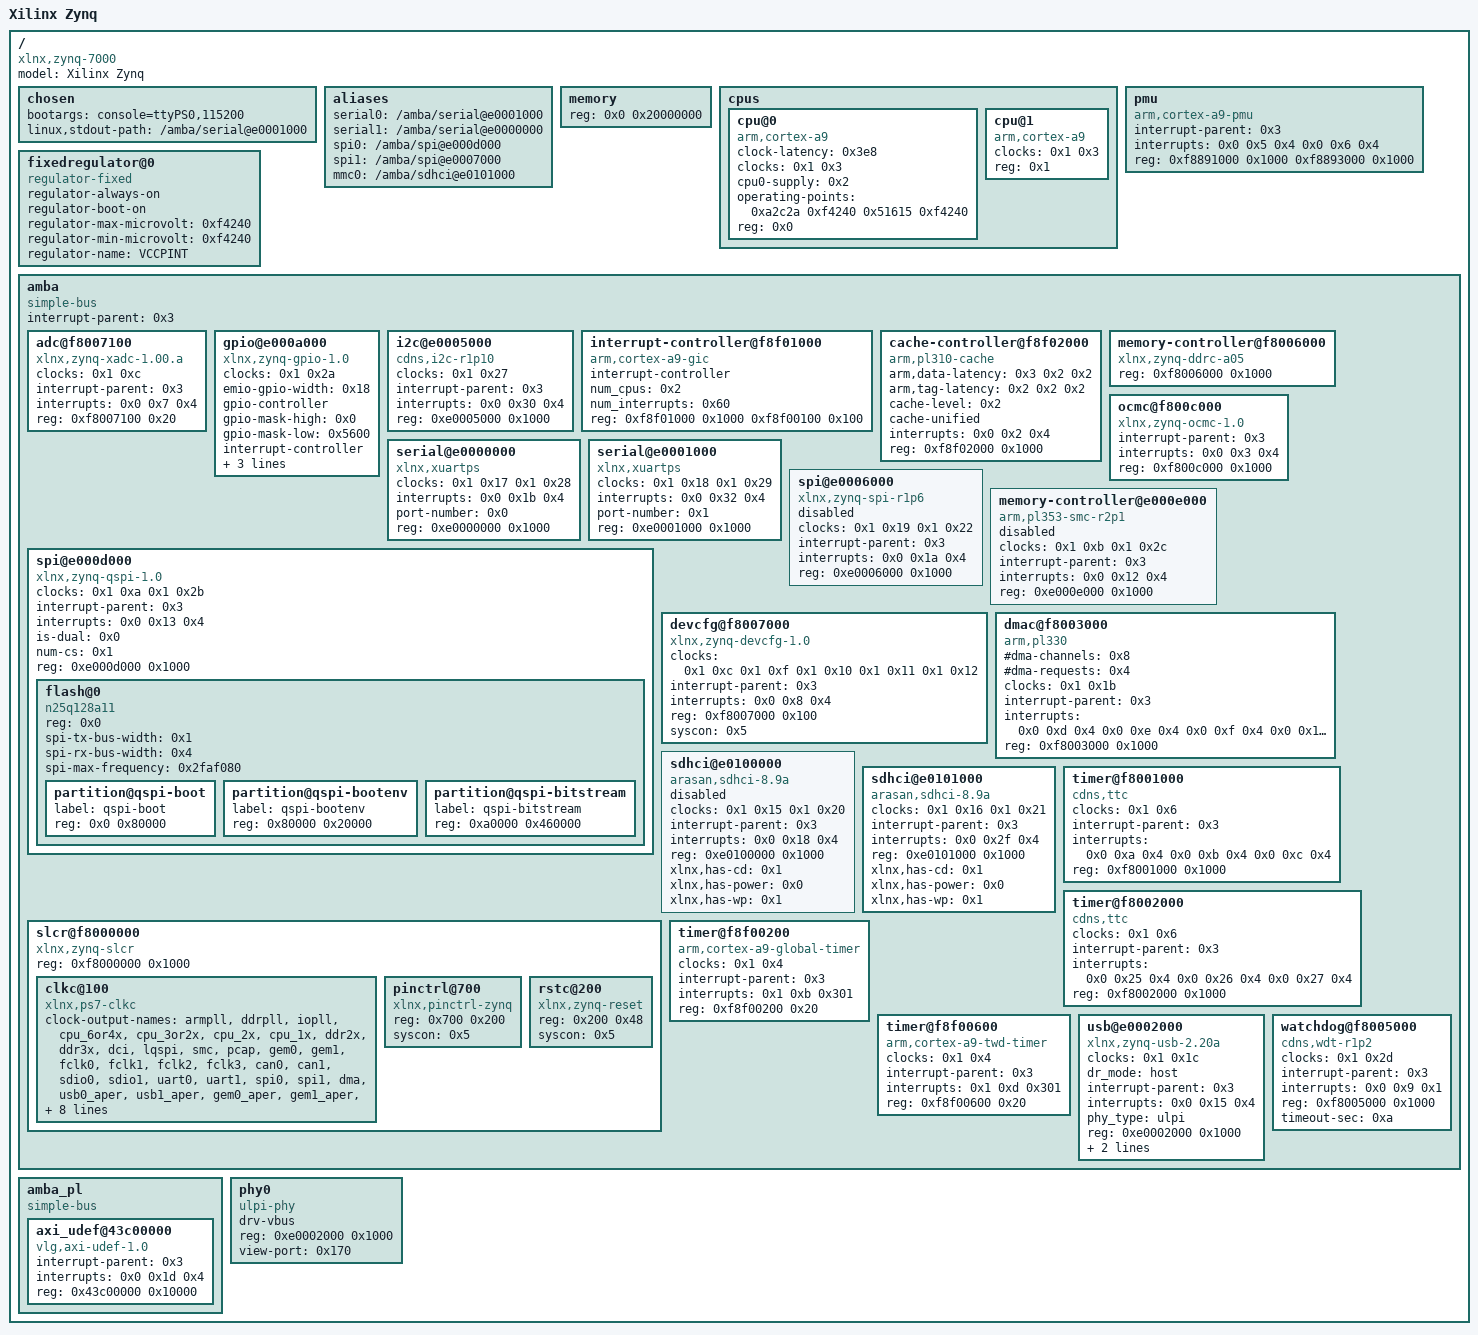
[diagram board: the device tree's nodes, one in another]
/dts-v1/;

/ {
	#address-cells = <0x1>;
	#size-cells = <0x1>;
	compatible = "xlnx,zynq-7000";
	model = "Xilinx Zynq";

	chosen {
		bootargs = "console=ttyPS0,115200";
		linux,stdout-path = "/amba/serial@e0001000";
	};

	aliases {
		serial0 = "/amba/serial@e0001000";
		serial1 = "/amba/serial@e0000000";
		spi0 = "/amba/spi@e000d000";
		spi1 = "/amba/spi@e0007000";
		mmc0 = "/amba/sdhci@e0101000";
	};


	memory {
		device_type = "memory";
		reg = <0x0 0x20000000>;
	};

	cpus {
		#address-cells = <0x1>;
		#size-cells = <0x0>;

		cpu@0 {
			clock-latency = <0x3e8>;
			clocks = <0x1 0x3>;
			compatible = "arm,cortex-a9";
			cpu0-supply = <0x2>;
			device_type = "cpu";
			operating-points = <0xa2c2a 0xf4240 0x51615 0xf4240>;
			reg = <0x0>;
		};

		cpu@1 {
			clocks = <0x1 0x3>;
			compatible = "arm,cortex-a9";
			device_type = "cpu";
			reg = <0x1>;
		};
	};

	pmu {
		compatible = "arm,cortex-a9-pmu";
		interrupt-parent = <0x3>;
		interrupts = <0x0 0x5 0x4 0x0 0x6 0x4>;
		reg = <0xf8891000 0x1000 0xf8893000 0x1000>;
	};

	fixedregulator@0 {
		compatible = "regulator-fixed";
		linux,phandle = <0x2>;
		phandle = <0x2>;
		regulator-always-on;
		regulator-boot-on;
		regulator-max-microvolt = <0xf4240>;
		regulator-min-microvolt = <0xf4240>;
		regulator-name = "VCCPINT";
	};




	amba {
		#address-cells = <0x1>;
		#size-cells = <0x1>;
		compatible = "simple-bus";
		interrupt-parent = <0x3>;
		linux,phandle = <0xa>;
		phandle = <0xa>;
		ranges;

		adc@f8007100 {
			clocks = <0x1 0xc>;
			compatible = "xlnx,zynq-xadc-1.00.a";
			interrupt-parent = <0x3>;
			interrupts = <0x0 0x7 0x4>;
			linux,phandle = <0xb>;
			phandle = <0xb>;
			reg = <0xf8007100 0x20>;
		};
		gpio@e000a000 {
			#gpio-cells = <0x2>;
			#interrupt-cells = <0x2>;
			clocks = <0x1 0x2a>;
			compatible = "xlnx,zynq-gpio-1.0";
			emio-gpio-width = <0x18>;
			gpio-controller;
			gpio-mask-high = <0x0>;
			gpio-mask-low = <0x5600>;
			interrupt-controller;
			interrupt-parent = <0x3>;
			interrupts = <0x0 0x14 0x4>;
			linux,phandle = <0x6>;
			phandle = <0x6>;
			reg = <0xe000a000 0x1000>;
		};
		i2c@e0005000 {
			#address-cells = <0x1>;
			#size-cells = <0x0>;
			clocks = <0x1 0x27>;
			compatible = "cdns,i2c-r1p10";
			interrupt-parent = <0x3>;
			interrupts = <0x0 0x30 0x4>;
			linux,phandle = <0xf>;
			phandle = <0xf>;
			reg = <0xe0005000 0x1000>;
			status = "okay";
		};

		interrupt-controller@f8f01000 {
			#interrupt-cells = <0x3>;
			compatible = "arm,cortex-a9-gic";
			interrupt-controller;
			linux,phandle = <0x3>;
			num_cpus = <0x2>;
			num_interrupts = <0x60>;
			phandle = <0x3>;
			reg = <0xf8f01000 0x1000 0xf8f00100 0x100>;
		};

		cache-controller@f8f02000 {
			arm,data-latency = <0x3 0x2 0x2>;
			arm,tag-latency = <0x2 0x2 0x2>;
			cache-level = <0x2>;
			cache-unified;
			compatible = "arm,pl310-cache";
			interrupts = <0x0 0x2 0x4>;
			linux,phandle = <0x10>;
			phandle = <0x10>;
			reg = <0xf8f02000 0x1000>;
		};
		memory-controller@f8006000 {
			compatible = "xlnx,zynq-ddrc-a05";
			linux,phandle = <0x11>;
			phandle = <0x11>;
			reg = <0xf8006000 0x1000>;
		};

		ocmc@f800c000 {
			compatible = "xlnx,zynq-ocmc-1.0";
			interrupt-parent = <0x3>;
			interrupts = <0x0 0x3 0x4>;
			linux,phandle = <0x12>;
			phandle = <0x12>;
			reg = <0xf800c000 0x1000>;
		};
		serial@e0000000 {
			clock-names = "uart_clk", "pclk";
			clocks = <0x1 0x17 0x1 0x28>;
			compatible = "xlnx,xuartps", "cdns,uart-r1p8";
			device_type = "serial";
			interrupts = <0x0 0x1b 0x4>;
			linux,phandle = <0x13>;
			phandle = <0x13>;
			port-number = <0x0>;
			reg = <0xe0000000 0x1000>;
			status = "okay";
		};

		serial@e0001000 {
			clock-names = "uart_clk", "pclk";
			clocks = <0x1 0x18 0x1 0x29>;
			compatible = "xlnx,xuartps", "cdns,uart-r1p8";
			device_type = "serial";
			interrupts = <0x0 0x32 0x4>;
			linux,phandle = <0x14>;
			phandle = <0x14>;
			port-number = <0x1>;
			reg = <0xe0001000 0x1000>;
			status = "okay";
		};
		spi@e0006000 {
			#address-cells = <0x1>;
			#size-cells = <0x0>;
			clock-names = "ref_clk", "pclk";
			clocks = <0x1 0x19 0x1 0x22>;
			compatible = "xlnx,zynq-spi-r1p6";
			interrupt-parent = <0x3>;
			interrupts = <0x0 0x1a 0x4>;
			linux,phandle = <0x15>;
			phandle = <0x15>;
			reg = <0xe0006000 0x1000>;
			status = "disabled";
		};

		spi@e000d000 {
			#address-cells = <0x1>;
			#size-cells = <0x0>;
			clock-names = "ref_clk", "pclk";
			clocks = <0x1 0xa 0x1 0x2b>;
			compatible = "xlnx,zynq-qspi-1.0";
			interrupt-parent = <0x3>;
			interrupts = <0x0 0x13 0x4>;
			is-dual = <0x0>;
			linux,phandle = <0x17>;
			num-cs = <0x1>;
			phandle = <0x17>;
			reg = <0xe000d000 0x1000>;
			status = "okay";

			flash@0 {
				compatible = "n25q128a11";
				reg = <0x0>;
				spi-tx-bus-width = <0x1>;
				spi-rx-bus-width = <0x4>;
				spi-max-frequency = <0x2faf080>;
				#address-cells = <0x1>;
				#size-cells = <0x1>;

				partition@qspi-boot {
					label = "qspi-boot";
					reg = <0x0 0x80000>;
				};

				partition@qspi-bootenv {
					label = "qspi-bootenv";
					reg = <0x80000 0x20000>;
				};

				partition@qspi-bitstream {
					label = "qspi-bitstream";
					reg = <0xa0000 0x460000>;
				};

			};
		};
		memory-controller@e000e000 {
			#address-cells = <0x1>;
			#size-cells = <0x1>;
			clock-names = "memclk", "aclk";
			clocks = <0x1 0xb 0x1 0x2c>;
			compatible = "arm,pl353-smc-r2p1";
			interrupt-parent = <0x3>;
			interrupts = <0x0 0x12 0x4>;
			linux,phandle = <0x18>;
			phandle = <0x18>;
			ranges;
			reg = <0xe000e000 0x1000>;
			status = "disabled";
		};

		devcfg@f8007000 {
			clock-names = "ref_clk", "fclk0", "fclk1", "fclk2", "fclk3";
			clocks = <0x1 0xc 0x1 0xf 0x1 0x10 0x1 0x11 0x1 0x12>;
			compatible = "xlnx,zynq-devcfg-1.0";
			interrupt-parent = <0x3>;
			interrupts = <0x0 0x8 0x4>;
			linux,phandle = <0x22>;
			phandle = <0x22>;
			reg = <0xf8007000 0x100>;
			syscon = <0x5>;
		};

		dmac@f8003000 {
			#dma-cells = <0x1>;
			#dma-channels = <0x8>;
			#dma-requests = <0x4>;
			clock-names = "apb_pclk";
			clocks = <0x1 0x1b>;
			compatible = "arm,pl330", "arm,primecell";
			interrupt-names = "abort", "dma0", "dma1", "dma2", "dma3", "dma4", "dma5", "dma6", "dma7";
			interrupt-parent = <0x3>;
			interrupts = <0x0 0xd 0x4 0x0 0xe 0x4 0x0 0xf 0x4 0x0 0x10 0x4 0x0 0x11 0x4 0x0 0x28 0x4 0x0 0x29 0x4 0x0 0x2a 0x4 0x0 0x2b 0x4>;
			linux,phandle = <0x21>;
			phandle = <0x21>;
			reg = <0xf8003000 0x1000>;
		};





		sdhci@e0100000 {
			clock-names = "clk_xin", "clk_ahb";
			clocks = <0x1 0x15 0x1 0x20>;
			compatible = "arasan,sdhci-8.9a";
			interrupt-parent = <0x3>;
			interrupts = <0x0 0x18 0x4>;
			linux,phandle = <0x1d>;
			phandle = <0x1d>;
			reg = <0xe0100000 0x1000>;
			status = "disabled";
			xlnx,has-cd = <0x1>;
			xlnx,has-power = <0x0>;
			xlnx,has-wp = <0x1>;
		};

		sdhci@e0101000 {
			clock-names = "clk_xin", "clk_ahb";
			clocks = <0x1 0x16 0x1 0x21>;
			compatible = "arasan,sdhci-8.9a";
			interrupt-parent = <0x3>;
			interrupts = <0x0 0x2f 0x4>;
			linux,phandle = <0x1e>;
			phandle = <0x1e>;
			reg = <0xe0101000 0x1000>;
			status = "okay";
			xlnx,has-cd = <0x1>;
			xlnx,has-power = <0x0>;
			xlnx,has-wp = <0x1>;
		};


		slcr@f8000000 {
			#address-cells = <0x1>;
			#size-cells = <0x1>;
			compatible = "xlnx,zynq-slcr", "syscon", "simple-bus";
			linux,phandle = <0x5>;
			phandle = <0x5>;
			ranges;
			reg = <0xf8000000 0x1000>;

			clkc@100 {
				#clock-cells = <0x1>;
				clock-output-names = "armpll", "ddrpll", "iopll", "cpu_6or4x", "cpu_3or2x", "cpu_2x", "cpu_1x", "ddr2x", "ddr3x", "dci", "lqspi", "smc", "pcap", "gem0", "gem1", "fclk0", "fclk1", "fclk2", "fclk3", "can0", "can1", "sdio0", "sdio1", "uart0", "uart1", "spi0", "spi1", "dma", "usb0_aper", "usb1_aper", "gem0_aper", "gem1_aper", "sdio0_aper", "sdio1_aper", "spi0_aper", "spi1_aper", "can0_aper", "can1_aper", "i2c0_aper", "i2c1_aper", "uart0_aper", "uart1_aper", "gpio_aper", "lqspi_aper", "smc_aper", "swdt", "dbg_trc", "dbg_apb";
				compatible = "xlnx,ps7-clkc";
				fclk-enable = <0xf>;
				linux,phandle = <0x1>;
				phandle = <0x1>;
				ps-clk-frequency = <0x1fca055>;
				reg = <0x100 0x100>;
			};

			pinctrl@700 {
				compatible = "xlnx,pinctrl-zynq";
				linux,phandle = <0x20>;
				phandle = <0x20>;
				reg = <0x700 0x200>;
				syscon = <0x5>;
			};

			rstc@200 {
				#reset-cells = <0x1>;
				compatible = "xlnx,zynq-reset";
				linux,phandle = <0x1f>;
				phandle = <0x1f>;
				reg = <0x200 0x48>;
				syscon = <0x5>;
			};
		};


		timer@f8001000 {
			clocks = <0x1 0x6>;
			compatible = "cdns,ttc";
			interrupt-parent = <0x3>;
			interrupts = <0x0 0xa 0x4 0x0 0xb 0x4 0x0 0xc 0x4>;
			linux,phandle = <0x24>;
			phandle = <0x24>;
			reg = <0xf8001000 0x1000>;
		};

		timer@f8002000 {
			clocks = <0x1 0x6>;
			compatible = "cdns,ttc";
			interrupt-parent = <0x3>;
			interrupts = <0x0 0x25 0x4 0x0 0x26 0x4 0x0 0x27 0x4>;
			linux,phandle = <0x25>;
			phandle = <0x25>;
			reg = <0xf8002000 0x1000>;
		};

		timer@f8f00200 {
			clocks = <0x1 0x4>;
			compatible = "arm,cortex-a9-global-timer";
			interrupt-parent = <0x3>;
			interrupts = <0x1 0xb 0x301>;
			linux,phandle = <0x23>;
			phandle = <0x23>;
			reg = <0xf8f00200 0x20>;
		};

		timer@f8f00600 {
			clocks = <0x1 0x4>;
			compatible = "arm,cortex-a9-twd-timer";
			interrupt-parent = <0x3>;
			interrupts = <0x1 0xd 0x301>;
			linux,phandle = <0x26>;
			phandle = <0x26>;
			reg = <0xf8f00600 0x20>;
		};

		usb@e0002000 {
			clocks = <0x1 0x1c>;
			compatible = "xlnx,zynq-usb-2.20a", "chipidea,usb2";
			dr_mode = "host";
			interrupt-parent = <0x3>;
			interrupts = <0x0 0x15 0x4>;
			linux,phandle = <0x27>;
			phandle = <0x27>;
			phy_type = "ulpi";
			reg = <0xe0002000 0x1000>;
			status = "okay";
			usb-phy = <0x7>;
			usb-reset = <0x6 0x30 0x0>;
		};

		watchdog@f8005000 {
			clocks = <0x1 0x2d>;
			compatible = "cdns,wdt-r1p2";
			interrupt-parent = <0x3>;
			interrupts = <0x0 0x9 0x1>;
			linux,phandle = <0x29>;
			phandle = <0x29>;
			reg = <0xf8005000 0x1000>;
			timeout-sec = <0xa>;
		};
	};

	amba_pl {
		#address-cells = <0x1>;
		#size-cells = <0x1>;
		compatible = "simple-bus";
		linux,phandle = <0x2a>;
		phandle = <0x2a>;
		ranges;

		axi_udef@43c00000 {
			#udef-cells = <0x1>;
			compatible = "vlg,axi-udef-1.0";
			interrupt-parent = <0x3>;
			interrupts = <0x0 0x1d 0x4>;
			reg = <0x43c00000 0x10000>;
		};
	};

	phy0 {
		#phy-cells = <0x0>;
		compatible = "ulpi-phy";
		drv-vbus;
		linux,phandle = <0x7>;
		phandle = <0x7>;
		reg = <0xe0002000 0x1000>;
		view-port = <0x170>;
	};

};
